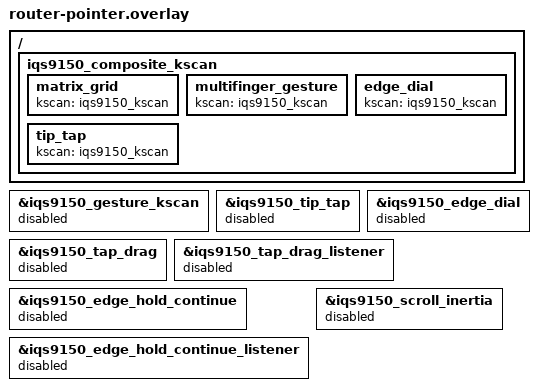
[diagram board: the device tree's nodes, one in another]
/* Diagnostic profile: session -> router -> pointer only.
 * 診断profile: session -> router -> pointer のみ。 */

/ {
    /* Keep the shipped composite as chosen: ZMK v0.3 derives its physical
     * layout from that chosen pair. Its driver instantiates every child,
     * including disabled ones, so replace omitted sources with inert mock
     * KSCAN rather than removing their child nodes. */
    iqs9150_composite_kscan {
        matrix_grid { kscan = <&iqs9150_kscan>; };
        multifinger_gesture { kscan = <&iqs9150_kscan>; };
        edge_dial { kscan = <&iqs9150_kscan>; };
        tip_tap { kscan = <&iqs9150_kscan>; };
    };
};

&iqs9150_gesture_kscan { status = "disabled"; };
&iqs9150_tip_tap { status = "disabled"; };
&iqs9150_edge_dial { status = "disabled"; };
&iqs9150_tap_drag { status = "disabled"; };
&iqs9150_tap_drag_listener { status = "disabled"; };
&iqs9150_edge_hold_continue { status = "disabled"; };
&iqs9150_edge_hold_continue_listener { status = "disabled"; };
&iqs9150_scroll_inertia { status = "disabled"; };
